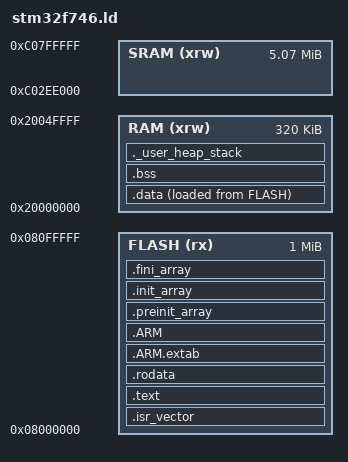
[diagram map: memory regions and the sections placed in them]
/*
 * Default linker script for Cortex-M (it includes specifics for STM32F[34]xx).
 * Based on GNU ARM Eclipse & STM32F7Cube templates
 */

/* Boot entry (defined in startup_stm32f746xx.s) */
ENTRY(Reset_Handler)

/* Specify the memory areas */
MEMORY {
  FLASH (rx)  : ORIGIN = 0x08000000, LENGTH = 1024K
  RAM (xrw)   : ORIGIN = 0x20000000, LENGTH = 320K
  /*
   * SRAM starts at 0xC0000000, but we reserve memory
   * for two LCD screen buffers (800 * 480 * 4 * 2)
   */
  SRAM (xrw)  : ORIGIN = 0xC02EE000, LENGTH = 5192K
}

/* Highest address of the user mode stack */
__stack = ORIGIN(RAM) + LENGTH(RAM);
_estack = __stack; /* STM specific */

/* Define SRAM region limits */
_sram_start = ORIGIN(SRAM);
_sram_end = ORIGIN(SRAM) + LENGTH(SRAM);

/* Generate a link error if heap and stack don't fit into RAM */
_Min_Heap_Size = 0x200;      /* required amount of heap  */
_Min_Stack_Size = 0x400; /* required amount of stack */

/* Define output sections */
SECTIONS {
  /*
   * For Cortex-M devices, the beginning of the startup code is stored in
   * the .isr_vector section, which goes to FLASH.
   */
  .isr_vector : ALIGN(4) {
    KEEP(*(.isr_vector)) /* ISR jump table */
    . = ALIGN(4);
  } >FLASH

  /* Program code and other data goes into FLASH */
  .text : ALIGN(4) {
    *(.text .text.*)
    /*
		 * Stub sections generated by the linker, to glue together
		 * ARM and Thumb code. .glue_7 is used for ARM code calling
		 * Thumb code, and .glue_7t is used for Thumb code calling
		 * ARM code. Apparently always generated by the linker, for some
		 * architectures, so better leave them here.
		 */
    *(.glue_7 .glue_7t)
    *(.eh_frame)

    KEEP (*(.init))
    KEEP (*(.fini))

    . = ALIGN(4);
    _etext = .;        /* define a global symbols at end of code */
  } >FLASH

  /* Constant data (constants, strings, etc.) goes into FLASH */
  .rodata : ALIGN(4) {
    *(.rodata .rodata*)
    . = ALIGN(4);
  } >FLASH

  .ARM.extab : ALIGN(4) {
    *(.ARM.extab* .gnu.linkonce.armextab.*)
  } >FLASH

  .ARM : ALIGN(4) {
    __exidx_start = .;
    *(.ARM.exidx* .gnu.linkonce.armexidx.*)
    __exidx_end = .;
  } >FLASH

  .preinit_array : {
    PROVIDE_HIDDEN (__preinit_array_start = .);
    KEEP (*(.preinit_array*))
    PROVIDE_HIDDEN (__preinit_array_end = .);
  } >FLASH

  .init_array : {
    PROVIDE_HIDDEN (__init_array_start = .);
    KEEP (*(SORT(.init_array.*)))
    KEEP (*(.init_array*))
    PROVIDE_HIDDEN (__init_array_end = .);
  } >FLASH

  .fini_array : {
    PROVIDE_HIDDEN (__fini_array_start = .);
    KEEP (*(SORT(.fini_array.*)))
    KEEP (*(.fini_array*))
    PROVIDE_HIDDEN (__fini_array_end = .);
  } >FLASH

  /* used by the startup to initialize data */
  _sidata = LOADADDR(.data);

  /* Initialized data sections goes into RAM, load LMA copy after code */
  .data : ALIGN(4) {
    _sdata = .;        /* create a global symbol at data start */
    *(.data)           /* .data sections */
    *(.data*)          /* .data* sections */

    . = ALIGN(4);
    _edata = .;        /* define a global symbol at data end */
  } >RAM AT> FLASH

  
  /* Uninitialized data section */
  .bss (NOLOAD) : ALIGN(4) {
    /* This is used by the startup in order to initialize the .bss secion */
    _sbss = .;         /* define a global symbol at bss start */
    __bss_start__ = _sbss;
    *(.bss .bss*)
    *(COMMON)

    . = ALIGN(4);
    _ebss = .;         /* define a global symbol at bss end */
    __bss_end__ = _ebss;
  } >RAM

  /* User_heap_stack section, used to check that there is enough RAM left */
  ._user_heap_stack : ALIGN(8) {
    PROVIDE ( end = . );
    PROVIDE ( _end = . );
    . = . + _Min_Heap_Size;
    . = . + _Min_Stack_Size;
    . = ALIGN(8);
  } >RAM

  /* Remove information from the standard libraries */
  /DISCARD/ :
  {
    libc.a ( * )
    libm.a ( * )
    libgcc.a ( * )
  }

  .ARM.attributes 0 : { *(.ARM.attributes) }
}
